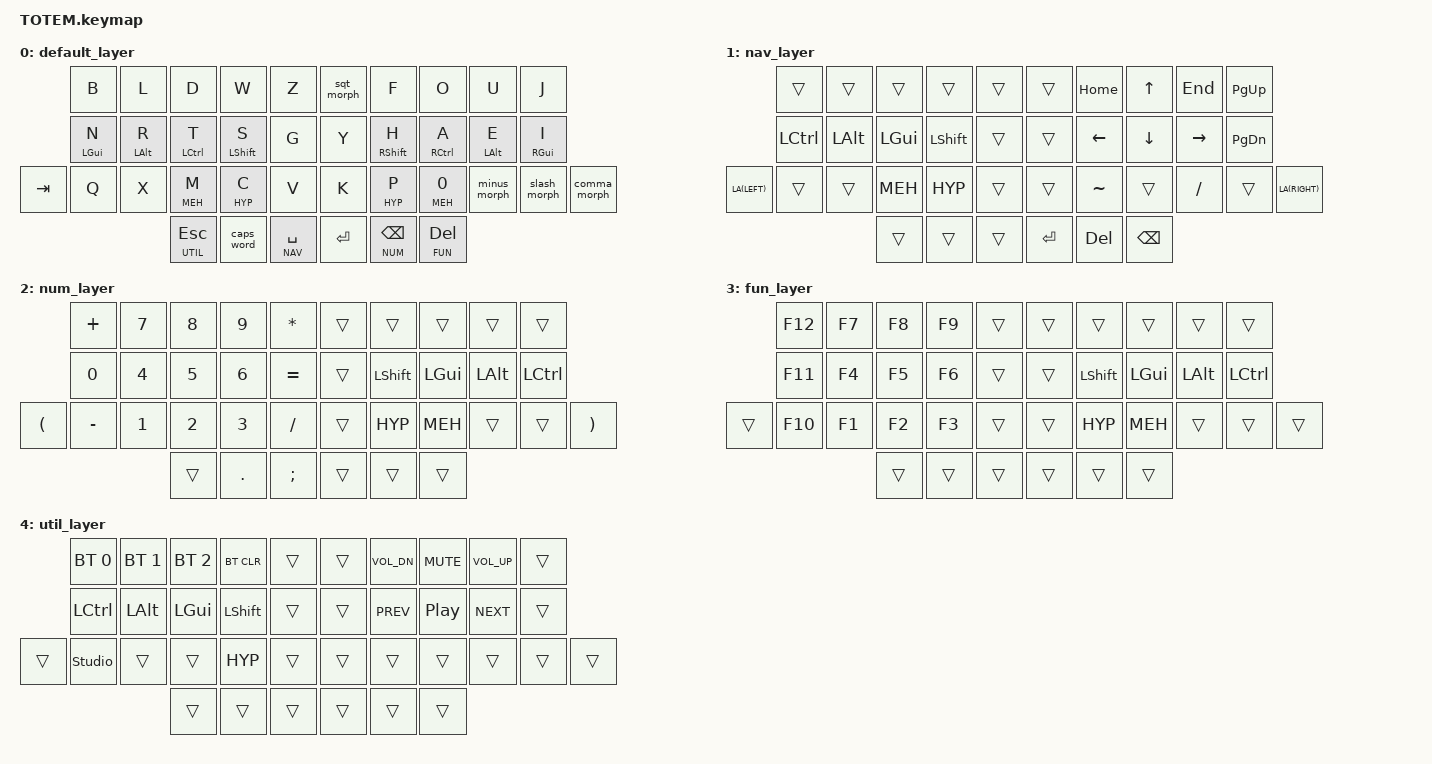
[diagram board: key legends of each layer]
// Copyright (c) 2022 The ZMK Contributors
// SPDX-License-Identifier: MIT

#include "../zmk-nodefree-config/helper.h"
#include "../zmk-nodefree-config/keypos_def/keypos_38keys.h"
#include <behaviors.dtsi>
#include <dt-bindings/zmk/keys.h>
#include <dt-bindings/zmk/bt.h>

#define XXX &none
#define TODO ___
#define ___ &trans

#define BASE 0
#define NAV 1
#define NUM 2
#define FUN 3
#define UTIL 4

#include "combos.dtsi"

// navigation bindings for back/forward and prev tab/next tab
#define BACK &kp LG(LBKT)
#define FWD &kp LG(RBKT)

// hyper and meh keys
#define HYP LS(LC(LA(LGUI)))
#define MEH LS(LC(LALT))

/* ------------------------ general config ----------------------- */

#define QUICK_TAP_MS 175

// smart-layer config
&caps_word {  
    // /delete-property/ ignore-modifiers; // mods deactivate, requires PR #1451
    /delete-property/ ignore-numbers;
    continue-list = <BACKSPACE ENTER DELETE UNDERSCORE MINUS>;
};

// key-repeat config
&key_repeat {
    usage-pages = <HID_USAGE_KEY HID_USAGE_CONSUMER>; // repeat all keys
};

// sticky key aka 'one-shot mods'
&sk {
    release-after-ms = <2000>;
    quick-release;
};

// default layer-tap config
&lt {  
    flavor = "balanced";
    tapping-term-ms = <200>;
    quick-tap-ms = <QUICK_TAP_MS>;
};

#define KEYS_L LT0 LT1 LT2 LT3 LT4 LM0 LM1 LM2 LM3 LM4 LB0 LB1 LB2 LB3 LB4  // left hand
#define KEYS_R RT0 RT1 RT2 RT3 RT4 RM0 RM1 RM2 RM3 RM4 RB0 RB1 RB2 RB3 RB4  // right hand
#define THUMBS LH2 LH1 LH0 RH0 RH1 RH2                                      // thumbs

#define MAKE_HRM(NAME, HOLD, TAP, TRIGGER_POS) \
    ZMK_BEHAVIOR(NAME, hold_tap, \
        flavor = "balanced"; \
        tapping-term-ms = <280>; \
        quick-tap-ms = <QUICK_TAP_MS>; \
        require-prior-idle-ms = <150>; \
        bindings = <HOLD>, <TAP>; \
        hold-trigger-key-positions = <TRIGGER_POS>; \
        hold-trigger-on-release; \
    )
MAKE_HRM(hml, &kp, &kp, KEYS_R THUMBS)  // left-hand HRMs
MAKE_HRM(hmr, &kp, &kp, KEYS_L THUMBS)  // right-hand HRMs

// special HRMs for the right meh key, as it involves a modmorph
MAKE_HRM(hmr_meh, &kp, &dot_morph, KEYS_L THUMBS)
// MAKE_HRM(hmr_lpar, &kp, &lpar, KEYS_L THUMBS)    // "    "   "   "
// MAKE_HRM(hmr_rpar, &kp, &rpar, KEYS_L THUMBS)    // "    "   "   "

// mod_morph keys
// tap: forward slash | shift + tap: less than
ZMK_BEHAVIOR(slash_morph, mod_morph,
    bindings = <&kp FSLH>, <&kp LT>;
    mods = <(MOD_LSFT|MOD_RSFT)>;
)

// tap: dot | shift + tap: greater than
ZMK_BEHAVIOR(dot_morph, mod_morph,
    bindings = <&kp DOT>, <&kp GT>;
    mods = <(MOD_LSFT|MOD_RSFT)>;
)

// tap: minus | shift + tap: double quote 
ZMK_BEHAVIOR(minus_morph, mod_morph,
    bindings = <&kp MINUS>, <&kp DQT>;
    mods = <(MOD_LSFT|MOD_RSFT)>;
)

// tap: comma | shift + tap: qmark 
ZMK_BEHAVIOR(comma_morph, mod_morph,
    bindings = <&kp COMMA>, <&kp QMARK>;
    mods = <(MOD_LSFT|MOD_RSFT)>;
)

// tap: single quote | shift + tap: underscore 
ZMK_BEHAVIOR(sqt_morph, mod_morph,
    bindings = <&kp SQT>, <&kp UNDER>;
    mods = <(MOD_LSFT|MOD_RSFT)>;
)

/ {
// TODO: Add hyper key as HRM
    keymap {
        compatible = "zmk,keymap";
        default_layer { 
            bindings = <
            &kp B         &kp L         &kp D            &kp W            &kp Z              &sqt_morph    &kp F              &kp O            &kp U         &kp J 
            &hml LGUI N   &hml LALT R   &hml LCTRL T     &hml LSHFT S     &kp G              &kp Y         &hmr RSHFT H       &hmr RCTRL A     &hmr LALT E   &hmr RGUI I
&kp TAB     &kp Q         &kp X         &hml MEH M       &hml HYP C       &kp V              &kp K         &hmr HYP P         &hmr_meh MEH 0   &minus_morph  &slash_morph        &comma_morph
                                        &lt UTIL ESC     &caps_word       &lt NAV SPACE      &kp RET       &lt NUM BSPC       &lt FUN DEL
            >;
        };
        nav_layer { 
            bindings = <
            ___             ___           ___              ___              ___                ___           &kp HOME           &kp UP           &kp END       &kp PAGE_UP 
            &kp LCTRL       &kp LALT      &kp LGUI         &kp LSHFT        ___                ___           &kp LEFT           &kp DOWN         &kp RIGHT     &kp PAGE_DOWN
LA(LEFT)    ___             ___           &kp MEH          &kp HYP          ___                ___           &kp TILDE          ___              &kp FSLH      ___               LA(RIGHT)
                                          ___              ___              ___                &kp RET       &kp DEL            &kp BSPC
            >;
        }; 
        num_layer {
            bindings = <
            &kp PLUS       &kp N7        &kp N8            &kp  N9          &kp STAR           ___           ___                ___              ___           ___ 
            &kp N0         &kp N4        &kp N5            &kp  N6          &kp EQUAL          ___           &kp LSHFT          &kp LGUI         &kp LALT      &kp LCTRL
  &kp LPAR  &kp MINUS      &kp N1        &kp N2            &kp  N3          &kp FSLH           ___           &kp HYP            &kp MEH          ___           ___              &kp RPAR
                                         ___               &kp  DOT         &kp SEMI           ___           ___                ___
            >;
        };
        fun_layer {
            bindings = <
            &kp F12        &kp F7        &kp F8           &kp F9            ___                ___           ___                ___              ___           ___
            &kp F11        &kp F4        &kp F5           &kp F6            ___                ___           &kp LSHFT          &kp LGUI         &kp LALT      &kp LCTRL 
    ___     &kp F10        &kp F1        &kp F2           &kp F3            ___                ___           &kp HYP            &kp MEH          ___           ___             ___
                                         ___              ___               ___                ___           ___                ___
            >;
        };
        util_layer {
            bindings = <
            &bt BT_SEL 0   &bt BT_SEL 1  &bt BT_SEL 2     &bt BT_CLR        ___                ___           &kp C_VOL_DN      &kp C_MUTE        &kp C_VOL_UP  ___
            &kp LCTRL      &kp LALT      &kp LGUI         &kp LSHFT         ___                ___           &kp C_PREV        &kp C_PP          &kp C_NEXT    ___ 
    ___     &studio_unlock ___           ___              &kp HYP           ___                ___           ___               ___               ___           ___             ___
                                         ___              ___               ___                ___           ___               ___
            >;
        };  
    };
};
    
/* --------------------------------- combos --------------------------------- */
/*
   ╭────────────────────┬────────────────────╮     ╭─────────────────────┬─────────────────────╮
   │  0   1   2   3   4 │  5   6   7   8   9 │     │ LT4 LT3 LT2 LT1 LT0 │ RT0 RT1 RT2 RT3 RT4 │
   │ 10  11  12  13  14 │ 15  16  17  18  19 │     │ LM4 LM3 LM2 LM1 LM0 │ RM0 RM1 RM2 RM3 RM4 │
  20 21  22  23  24  25 │ 26  27  28  29  30 31  LB5 LB4 LB3 LB2 LB1 LB0 │ RB0 RB1 RB2 RB3 RB4 RB5
   ╰───────╮ 32  33  34 │ 35  36  37 ╭───────╯     ╰───────╮ LH2 LH1 LH0 │ RH0 RH1 RH2 ╭───────╯
           ╰────────────┴────────────╯                     ╰─────────────┴─────────────╯             */
// use global-quick-tap-ms for combos (requires PR 1387)
